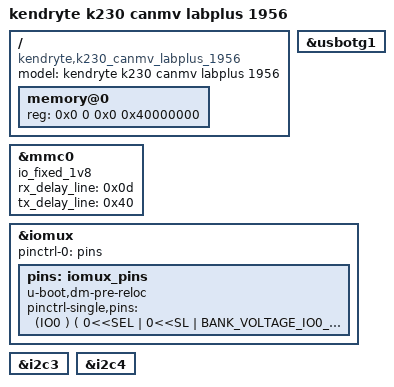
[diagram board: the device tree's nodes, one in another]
/* Copyright (c) 2023, Canaan Bright Sight Co., Ltd
 *
 * Redistribution and use in source and binary forms, with or without
 * modification, are permitted provided that the following conditions are met:
 * 1. Redistributions of source code must retain the above copyright
 * notice, this list of conditions and the following disclaimer.
 * 2. Redistributions in binary form must reproduce the above copyright
 * notice, this list of conditions and the following disclaimer in the
 * documentation and/or other materials provided with the distribution.
 *
 * THIS SOFTWARE IS PROVIDED BY THE COPYRIGHT HOLDERS AND
 * CONTRIBUTORS "AS IS" AND ANY EXPRESS OR IMPLIED WARRANTIES,
 * INCLUDING, BUT NOT LIMITED TO, THE IMPLIED WARRANTIES OF
 * MERCHANTABILITY AND FITNESS FOR A PARTICULAR PURPOSE ARE
 * DISCLAIMED. IN NO EVENT SHALL THE COPYRIGHT HOLDER OR
 * CONTRIBUTORS BE LIABLE FOR ANY DIRECT, INDIRECT, INCIDENTAL,
 * SPECIAL, EXEMPLARY, OR CONSEQUENTIAL DAMAGES (INCLUDING,
 * BUT NOT LIMITED TO, PROCUREMENT OF SUBSTITUTE GOODS OR
 * SERVICES; LOSS OF USE, DATA, OR PROFITS; OR BUSINESS
 * INTERRUPTION) HOWEVER CAUSED AND ON ANY THEORY OF LIABILITY,
 * WHETHER IN CONTRACT, STRICT LIABILITY, OR TORT (INCLUDING
 * NEGLIGENCE OR OTHERWISE) ARISING IN ANY WAY OUT OF THE USE
 * OF THIS SOFTWARE, EVEN IF ADVISED OF THE POSSIBILITY OF SUCH DAMAGE.
 */
// #include "k230_canmv_01studio.dts"
// &mmc0 {
// 	status = "okay";
// 	1-8-v;
// };


/* Copyright (c) 2023, Canaan Bright Sight Co., Ltd
 *
 * Redistribution and use in source and binary forms, with or without
 * modification, are permitted provided that the following conditions are met:
 * 1. Redistributions of source code must retain the above copyright
 * notice, this list of conditions and the following disclaimer.
 * 2. Redistributions in binary form must reproduce the above copyright
 * notice, this list of conditions and the following disclaimer in the
 * documentation and/or other materials provided with the distribution.
 *
 * THIS SOFTWARE IS PROVIDED BY THE COPYRIGHT HOLDERS AND
 * CONTRIBUTORS "AS IS" AND ANY EXPRESS OR IMPLIED WARRANTIES,
 * INCLUDING, BUT NOT LIMITED TO, THE IMPLIED WARRANTIES OF
 * MERCHANTABILITY AND FITNESS FOR A PARTICULAR PURPOSE ARE
 * DISCLAIMED. IN NO EVENT SHALL THE COPYRIGHT HOLDER OR
 * CONTRIBUTORS BE LIABLE FOR ANY DIRECT, INDIRECT, INCIDENTAL,
 * SPECIAL, EXEMPLARY, OR CONSEQUENTIAL DAMAGES (INCLUDING,
 * BUT NOT LIMITED TO, PROCUREMENT OF SUBSTITUTE GOODS OR
 * SERVICES; LOSS OF USE, DATA, OR PROFITS; OR BUSINESS
 * INTERRUPTION) HOWEVER CAUSED AND ON ANY THEORY OF LIABILITY,
 * WHETHER IN CONTRACT, STRICT LIABILITY, OR TORT (INCLUDING
 * NEGLIGENCE OR OTHERWISE) ARISING IN ANY WAY OUT OF THE USE
 * OF THIS SOFTWARE, EVEN IF ADVISED OF THE POSSIBILITY OF SUCH DAMAGE.
 */
/dts-v1/;
#include <dt-bindings/pinctrl/k230_evb.h>

#define BANK_VOLTAGE_IO0_IO1	 K230_MSC_1V8  // FIXED
#define BANK_VOLTAGE_IO2_IO13	 K230_MSC_3V3
#define BANK_VOLTAGE_IO14_IO25	 K230_MSC_3V3
#define BANK_VOLTAGE_IO26_IO37	 K230_MSC_3V3
#define BANK_VOLTAGE_IO38_IO49	 K230_MSC_3V3
#define BANK_VOLTAGE_IO50_IO61	 K230_MSC_3V3
#define BANK_VOLTAGE_IO62_IO63	 K230_MSC_1V8
#include "k230.dtsi"

/ {
	model = "kendryte k230 canmv labplus 1956";
	compatible = "kendryte,k230_canmv_labplus_1956";

	memory@0 {
		device_type = "memory";
		reg = <
				0x0 0 0x0 0x40000000
			  >;
	};
};

&mmc0 {
	status = "okay";
	io_fixed_1v8;
	rx_delay_line = <0x0d>;
	tx_delay_line = <0x40>;
};
&usbotg1 {
	status = "okay";
};
&iomux {
	pinctrl-names = "default";
	pinctrl-0 = <&pins>;

//	Please pay attention to the bank voltage! will damage the chip.
	pins: iomux_pins {
		u-boot,dm-pre-reloc;
		pinctrl-single,pins = <

		// S3 KEY
		(IO0 ) ( 0<<SEL | 0<<SL | BANK_VOLTAGE_IO0_IO1 <<MSC | 1<<IE | 1<<OE | 0<<PU | 0<<PD | 2<<DS | 0<<ST )
		(IO1 ) ( 1<<SEL | 0<<SL | BANK_VOLTAGE_IO0_IO1 <<MSC | 1<<IE | 1<<OE | 0<<PU | 0<<PD | 2<<DS | 0<<ST )

		// JP1-PIN7 JTAG
		(IO2 ) ( 1<<SEL | 0<<SL | BANK_VOLTAGE_IO2_IO13 <<MSC | 1<<IE | 1<<OE | 0<<PU | 0<<PD | 4<<DS | 0<<ST )
		(IO3 ) ( 1<<SEL | 0<<SL | BANK_VOLTAGE_IO2_IO13 <<MSC | 1<<IE | 1<<OE | 0<<PU | 0<<PD | 4<<DS | 0<<ST )
		(IO4 ) ( 1<<SEL | 0<<SL | BANK_VOLTAGE_IO2_IO13 <<MSC | 1<<IE | 1<<OE | 0<<PU | 0<<PD | 4<<DS | 0<<ST )
		(IO5 ) ( 1<<SEL | 0<<SL | BANK_VOLTAGE_IO2_IO13 <<MSC | 1<<IE | 1<<OE | 0<<PU | 0<<PD | 4<<DS | 0<<ST )
		(IO6 ) ( 1<<SEL | 0<<SL | BANK_VOLTAGE_IO2_IO13 <<MSC | 1<<IE | 1<<OE | 0<<PU | 0<<PD | 4<<DS | 0<<ST )

		// CAM2_I2C4_SCL
		(IO7 ) ( 2<<SEL | 0<<SL | BANK_VOLTAGE_IO2_IO13 <<MSC | 1<<IE | 1<<OE | 1<<PU | 0<<PD | 7<<DS | 1<<ST )
		// CAM2_I2C4_SDA
		(IO8 ) ( 2<<SEL | 0<<SL | BANK_VOLTAGE_IO2_IO13 <<MSC | 1<<IE | 1<<OE | 1<<PU | 0<<PD | 7<<DS | 1<<ST )
		// CAM0_GPIO9
		(IO9 ) ( 0<<SEL | 0<<SL | BANK_VOLTAGE_IO2_IO13 <<MSC | 1<<IE | 1<<OE | 0<<PU | 0<<PD | 7<<DS | 1<<ST )
		// CAM0_GPIO10 USB HOST POWER ENABLE
		(IO10) ( 0<<SEL | 0<<SL | BANK_VOLTAGE_IO2_IO13 <<MSC | 1<<IE | 1<<OE | 0<<PU | 0<<PD | 8<<DS | 1<<ST )
		// PORT4/P6 GPIO11/IIC2(SCL)/UART2(TX)
		(IO11) ( 0<<SEL | 0<<SL | BANK_VOLTAGE_IO2_IO13 <<MSC | 1<<IE | 0<<OE | 0<<PU | 0<<PD | 8<<DS | 0<<ST )
		// PORT4/P7 GPIO12/IIC2(SDA)/UART2(RX)
		(IO12) ( 0<<SEL | 0<<SL | BANK_VOLTAGE_IO2_IO13 <<MSC | 1<<IE | 0<<OE | 0<<PU | 0<<PD | 8<<DS | 0<<ST )
        //CAM2 CSI2 MCLK
		(IO13) ( 1<<SEL | 0<<SL | BANK_VOLTAGE_IO2_IO13 <<MSC | 0<<IE | 1<<OE | 0<<PU | 1<<PD | 4<<DS | 1<<ST )
	

		// GPIO14 ~ GPIO20
		// CAM2 CSI2 RST
		(IO14) ( 0<<SEL | 0<<SL | BANK_VOLTAGE_IO14_IO25<<MSC | 0<<IE | 1<<OE | 1<<PU | 0<<PD | 4<<DS | 1<<ST )
		// ACC INT 
		(IO15) ( 0<<SEL | 0<<SL | BANK_VOLTAGE_IO14_IO25<<MSC | 1<<IE | 0<<OE | 0<<PU | 0<<PD | 4<<DS | 1<<ST )
		// PRESS INT
		(IO16) ( 0<<SEL | 0<<SL | BANK_VOLTAGE_IO14_IO25<<MSC | 1<<IE | 0<<OE | 0<<PU | 0<<PD | 4<<DS | 1<<ST )
		// LIGHT INT
		(IO17) ( 0<<SEL | 0<<SL | BANK_VOLTAGE_IO14_IO25<<MSC | 1<<IE | 0<<OE | 0<<PU | 0<<PD | 4<<DS | 1<<ST )
		// IO18-21 NO USE
		(IO18) ( 0<<SEL | 0<<SL | BANK_VOLTAGE_IO14_IO25<<MSC | 1<<IE | 0<<OE | 0<<PU | 0<<PD | 15<<DS | 1<<ST )
		(IO19) ( 0<<SEL | 0<<SL | BANK_VOLTAGE_IO14_IO25<<MSC | 1<<IE | 0<<OE | 0<<PU | 0<<PD | 15<<DS | 1<<ST )
		(IO20) ( 0<<SEL | 0<<SL | BANK_VOLTAGE_IO14_IO25<<MSC | 1<<IE | 0<<OE | 0<<PU | 0<<PD | 15<<DS | 1<<ST )
		(IO21) ( 0<<SEL | 0<<SL | BANK_VOLTAGE_IO14_IO25<<MSC | 1<<IE | 0<<OE | 0<<PU | 0<<PD | 15<<DS | 1<<ST )
		// LCD_RST
		(IO22) ( 0<<SEL | 0<<SL | BANK_VOLTAGE_IO14_IO25<<MSC | 1<<IE | 1<<OE | 0<<PU | 0<<PD | 15<<DS | 1<<ST )
		// TP_INT
		(IO23) ( 0<<SEL | 0<<SL | BANK_VOLTAGE_IO14_IO25<<MSC | 1<<IE | 1<<OE | 0<<PU | 0<<PD | 15<<DS | 1<<ST )
		// TP_RST
		(IO24) ( 0<<SEL | 0<<SL | BANK_VOLTAGE_IO14_IO25<<MSC | 1<<IE | 1<<OE | 0<<PU | 0<<PD | 15<<DS | 1<<ST )
		// LCD_EN
		(IO25) ( 0<<SEL | 0<<SL | BANK_VOLTAGE_IO14_IO25<<MSC | 1<<IE | 1<<OE | 0<<PU | 0<<PD | 7<<DS | 1<<ST )

		(IO26) ( 0<<SEL | 0<<SL | BANK_VOLTAGE_IO26_IO37<<MSC | 1<<IE | 0<<OE | 0<<PU | 0<<PD | 7<<DS | 1<<ST )
		(IO27) ( 0<<SEL | 0<<SL | BANK_VOLTAGE_IO26_IO37<<MSC | 1<<IE | 0<<OE | 0<<PU | 0<<PD | 7<<DS | 1<<ST )
		(IO28) ( 0<<SEL | 0<<SL | BANK_VOLTAGE_IO26_IO37<<MSC | 1<<IE | 0<<OE | 0<<PU | 0<<PD | 7<<DS | 1<<ST )
		(IO29) ( 0<<SEL | 0<<SL | BANK_VOLTAGE_IO26_IO37<<MSC | 1<<IE | 0<<OE | 0<<PU | 0<<PD | 7<<DS | 1<<ST )
		(IO30) ( 0<<SEL | 0<<SL | BANK_VOLTAGE_IO26_IO37<<MSC | 1<<IE | 0<<OE | 0<<PU | 0<<PD | 7<<DS | 1<<ST )
		(IO31) ( 0<<SEL | 0<<SL | BANK_VOLTAGE_IO26_IO37<<MSC | 1<<IE | 0<<OE | 0<<PU | 0<<PD | 7<<DS | 1<<ST )
		(IO32) ( 0<<SEL | 0<<SL | BANK_VOLTAGE_IO26_IO37<<MSC | 0<<IE | 0<<OE | 0<<PU | 0<<PD | 7<<DS | 1<<ST )
		(IO33) ( 0<<SEL | 0<<SL | BANK_VOLTAGE_IO26_IO37<<MSC | 0<<IE | 0<<OE | 0<<PU | 0<<PD | 7<<DS | 1<<ST )
		(IO34) ( 0<<SEL | 0<<SL | BANK_VOLTAGE_IO26_IO37<<MSC |	1<<IE | 0<<OE | 0<<PU | 1<<PD | 7<<DS | 0<<ST )
		(IO35) ( 0<<SEL | 0<<SL | BANK_VOLTAGE_IO26_IO37<<MSC | 1<<IE | 0<<OE | 0<<PU | 0<<PD | 7<<DS | 1<<ST )
		(IO36) ( 0<<SEL | 0<<SL | BANK_VOLTAGE_IO26_IO37<<MSC | 1<<IE | 0<<OE | 0<<PU | 0<<PD | 7<<DS | 1<<ST )
		(IO37) ( 0<<SEL | 0<<SL | BANK_VOLTAGE_IO26_IO37<<MSC | 1<<IE | 0<<OE | 0<<PU | 0<<PD | 7<<DS | 1<<ST )

		// UART0_TXD
		(IO38) ( 1<<SEL | 0<<SL | BANK_VOLTAGE_IO38_IO49<<MSC | 0<<IE | 1<<OE | 0<<PU | 0<<PD | 7<<DS | 1<<ST )
		// UART0_RXD
		(IO39) ( 1<<SEL | 0<<SL | BANK_VOLTAGE_IO38_IO49<<MSC | 1<<IE | 0<<OE | 0<<PU | 0<<PD | 7<<DS | 1<<ST )

		// PORT3/P4 GPIO40/I2C1(SCL)/UART1(TX)
		(IO40) ( 0<<SEL | 0<<SL | BANK_VOLTAGE_IO38_IO49<<MSC | 1<<IE | 0<<OE | 0<<PU | 0<<PD | 7<<DS | 1<<ST )
		// PORT3/P4 GPIO41/I2C1(SDA)/UART1(RX)
		(IO41) ( 0<<SEL | 0<<SL | BANK_VOLTAGE_IO38_IO49<<MSC | 1<<IE | 0<<OE | 0<<PU | 0<<PD | 7<<DS | 1<<ST )

		// PORT5/P8 GPIO42/PWM0
		(IO42) ( 0<<SEL | 0<<SL | BANK_VOLTAGE_IO38_IO49<<MSC | 1<<IE | 0<<OE | 0<<PU | 0<<PD | 7<<DS | 1<<ST )
		// PORT5/P9 GPIO43/PWM1
		(IO43) ( 0<<SEL | 0<<SL | BANK_VOLTAGE_IO38_IO49<<MSC | 1<<IE | 0<<OE | 0<<PU | 0<<PD | 7<<DS | 1<<ST )

		// TP I2C3(SCL)
		(IO44) ( 2<<SEL | 0<<SL | BANK_VOLTAGE_IO38_IO49<<MSC | 1<<IE | 1<<OE | 1<<PU | 0<<PD | 7<<DS | 1<<ST )
		// TP I2C3(SDA)
		(IO45) ( 2<<SEL | 0<<SL | BANK_VOLTAGE_IO38_IO49<<MSC | 1<<IE | 1<<OE | 1<<PU | 0<<PD | 7<<DS | 1<<ST )

		// PORT6/P10 GPIO46/PWM2
		(IO46) ( 0<<SEL | 0<<SL | BANK_VOLTAGE_IO38_IO49<<MSC | 1<<IE | 1<<OE | 1<<PU | 0<<PD | 7<<DS | 1<<ST )
		// PORT6/P11 GPIO47/PWM3
		(IO47) ( 0<<SEL | 0<<SL | BANK_VOLTAGE_IO38_IO49<<MSC | 1<<IE | 1<<OE | 1<<PU | 0<<PD | 7<<DS | 1<<ST )

		// PORT2/P2 GPIO48/I2C0(SCL)/UART4(TX)
		(IO48) ( 0<<SEL | 0<<SL | BANK_VOLTAGE_IO38_IO49<<MSC | 1<<IE | 0<<OE | 0<<PU | 0<<PD | 7<<DS | 1<<ST )
		// PORT2/P2 GPIO49/I2C0(SDA)/UART4(RX)
		(IO49) ( 0<<SEL | 0<<SL | BANK_VOLTAGE_IO38_IO49<<MSC | 1<<IE | 0<<OE | 0<<PU | 0<<PD | 7<<DS | 1<<ST )

		// UART3_TXD
		(IO50) ( 1<<SEL | 0<<SL | BANK_VOLTAGE_IO50_IO61<<MSC | 0<<IE | 1<<OE | 0<<PU | 0<<PD | 7<<DS | 1<<ST )
		// UART3_RXD
		(IO51) ( 1<<SEL | 0<<SL | BANK_VOLTAGE_IO50_IO61<<MSC | 1<<IE | 0<<OE | 0<<PU | 0<<PD | 7<<DS | 1<<ST )

		// NO USE
		(IO52) ( 0<<SEL | 0<<SL | BANK_VOLTAGE_IO50_IO61<<MSC | 1<<IE | 0<<OE | 0<<PU | 0<<PD | 7<<DS | 1<<ST )
		(IO53) ( 0<<SEL | 0<<SL | BANK_VOLTAGE_IO50_IO61<<MSC | 1<<IE | 0<<OE | 0<<PU | 0<<PD | 7<<DS | 1<<ST )

		// MMC1 -> WIFI
		(IO54) ( 2<<SEL | 0<<SL | BANK_VOLTAGE_IO50_IO61<<MSC | 1<<IE | 1<<OE | 1<<PU | 0<<PD | 7<<DS | 1<<ST )
		(IO55) ( 2<<SEL | 0<<SL | BANK_VOLTAGE_IO50_IO61<<MSC | 0<<IE | 1<<OE | 0<<PU | 0<<PD | 7<<DS | 1<<ST )
		(IO56) ( 2<<SEL | 0<<SL | BANK_VOLTAGE_IO50_IO61<<MSC | 1<<IE | 1<<OE | 1<<PU | 0<<PD | 7<<DS | 1<<ST )
		(IO57) ( 2<<SEL | 0<<SL | BANK_VOLTAGE_IO50_IO61<<MSC | 1<<IE | 1<<OE | 1<<PU | 0<<PD | 7<<DS | 1<<ST )
		(IO58) ( 2<<SEL | 0<<SL | BANK_VOLTAGE_IO50_IO61<<MSC | 1<<IE | 1<<OE | 1<<PU | 0<<PD | 7<<DS | 1<<ST )
		(IO59) ( 2<<SEL | 0<<SL | BANK_VOLTAGE_IO50_IO61<<MSC | 1<<IE | 1<<OE | 1<<PU | 0<<PD | 7<<DS | 1<<ST )
		// WIFI_REGON
		(IO60) ( 0<<SEL | 0<<SL | BANK_VOLTAGE_IO50_IO61<<MSC | 1<<IE | 1<<OE | 1<<PU | 0<<PD | 7<<DS | 1<<ST )
		// NO USE
		(IO61) ( 0<<SEL | 0<<SL | BANK_VOLTAGE_IO50_IO61<<MSC | 1<<IE | 0<<OE | 0<<PU | 0<<PD | 7<<DS | 1<<ST )

		// NO USE
		(IO62) ( 0<<SEL | 0<<SL | BANK_VOLTAGE_IO62_IO63<<MSC | 0<<IE | 0<<OE | 0<<PU | 1<<PD | 4<<DS | 1<<ST )
		(IO63) ( 0<<SEL | 0<<SL | BANK_VOLTAGE_IO62_IO63<<MSC | 0<<IE | 0<<OE | 0<<PU | 1<<PD | 4<<DS | 1<<ST )
		>;
	};
};

&i2c3 {
	status = "okay";
};

&i2c4 {
	status = "okay";
};
